# ESP32-H2 register map
Vendor: ESPRESSIF SYSTEMS (SHANGHAI) CO., LTD.; Series: ESP32 H-Series; File version: 12
CPU: RV32IMAC r0p0, little endian, no MPU, no FPU, 0 interrupt priority bits
Address unit: 32 bits
Registers are 32-bit, read-write, reset 0x0 unless marked. A register's access mark holds for its fields unless they carry their own. Offsets are from the block's base; [hi:lo] are bit positions; {n}, {i} and the like mark numbered series.

## LP_PERI — LP_PERI Peripheral
Base 0x600B2800
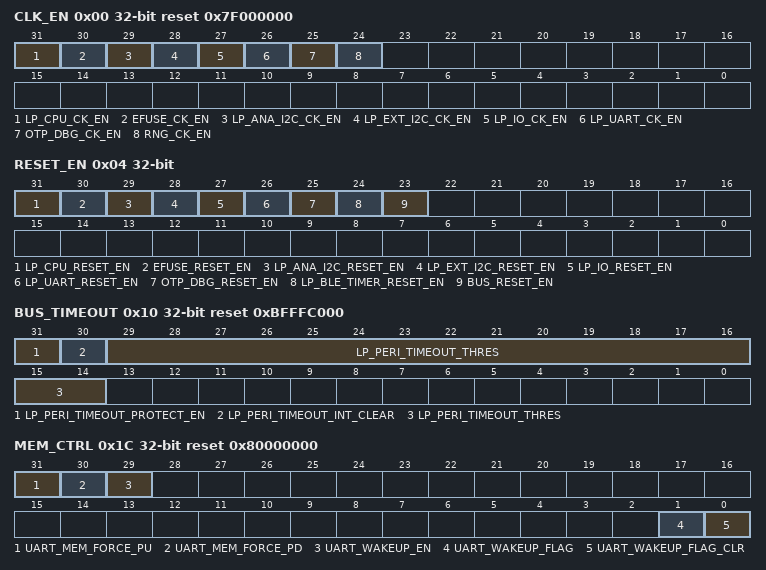
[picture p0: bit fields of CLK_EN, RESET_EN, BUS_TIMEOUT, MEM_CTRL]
0x00 CLK_EN reset 0x7F000000 — need_des
  [31] LP_CPU_CK_EN — need_des
  [30] EFUSE_CK_EN — need_des
  [29] LP_ANA_I2C_CK_EN — need_des
  [28] LP_EXT_I2C_CK_EN — need_des
  [27] LP_IO_CK_EN — need_des
  [26] LP_UART_CK_EN — need_des
  [25] OTP_DBG_CK_EN — need_des
  [24] RNG_CK_EN — need_des
0x04 RESET_EN access per field — need_des
  [31] LP_CPU_RESET_EN wo — need_des
  [30] EFUSE_RESET_EN rw — need_des
  [29] LP_ANA_I2C_RESET_EN rw — need_des
  [28] LP_EXT_I2C_RESET_EN rw — need_des
  [27] LP_IO_RESET_EN rw — need_des
  [26] LP_UART_RESET_EN rw — need_des
  [25] OTP_DBG_RESET_EN rw — need_des
  [24] LP_BLE_TIMER_RESET_EN rw — need_des
  [23] BUS_RESET_EN wo — need_des
0x08 RNG_DATA ro — need_des
  [31:0] RND_DATA
0x0C CPU reset 0x80000000 — need_des
  [31] LPCORE_DBGM_UNAVALIABLE
0x10 BUS_TIMEOUT access per field reset 0xBFFFC000 — need_des
  [31] LP_PERI_TIMEOUT_PROTECT_EN rw — need_des
  [30] LP_PERI_TIMEOUT_INT_CLEAR wo — need_des
  [29:14] LP_PERI_TIMEOUT_THRES rw — need_des
0x14 BUS_TIMEOUT_ADDR ro — need_des
  [31:0] LP_PERI_TIMEOUT_ADDR
0x18 BUS_TIMEOUT_UID ro — need_des
  [6:0] LP_PERI_TIMEOUT_UID
0x1C MEM_CTRL access per field reset 0x80000000 — need_des
  [31] UART_MEM_FORCE_PU rw — need_des
  [30] UART_MEM_FORCE_PD rw — need_des
  [29] UART_WAKEUP_EN rw — need_des
  [1] UART_WAKEUP_FLAG rw — need_des
  [0] UART_WAKEUP_FLAG_CLR wo — need_des
0x20 INTERRUPT_SOURCE ro — need_des
  [5:0] LP_INTERRUPT_SOURCE — BIT5~BIT0: pmu_lp_int, modem_lp_int, lp_timer_lp_int, lp_uart_int, lp_i2c_int, lp_io_int
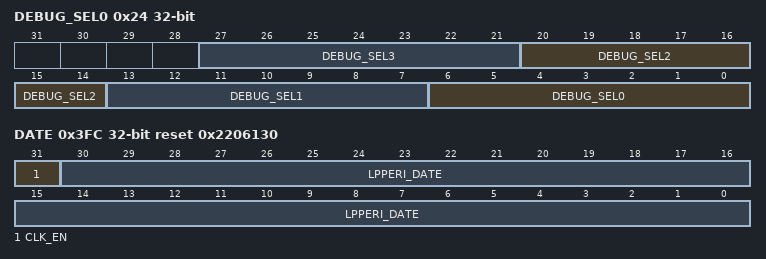
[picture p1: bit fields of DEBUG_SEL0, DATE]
0x24 DEBUG_SEL0 — need des
  [7n+6:7n] DEBUG_SEL{n} (n=0..3) — need des
0x28 DEBUG_SEL1 — need des
  [6:0] DEBUG_SEL4
0x3FC DATE reset 0x2206130 — need_des
  [31] CLK_EN — need_des
  [30:0] LPPERI_DATE — need_des

## LP_ANA — LP_ANA Peripheral
Base 0x600B2C00
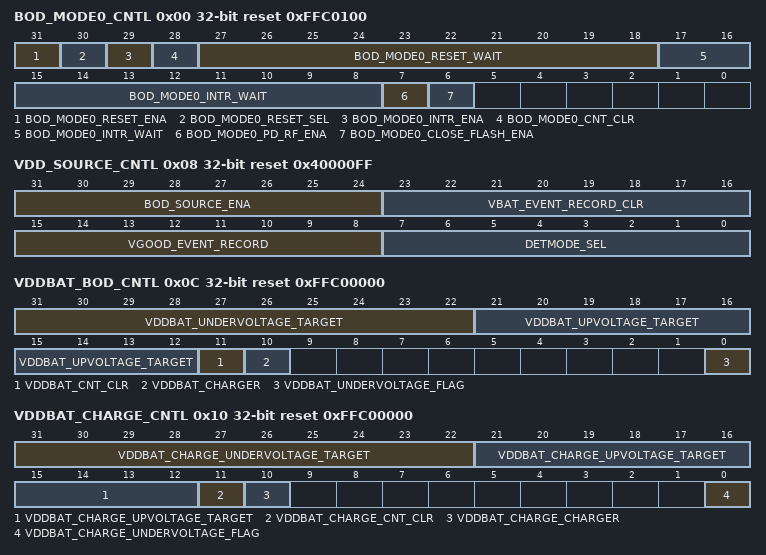
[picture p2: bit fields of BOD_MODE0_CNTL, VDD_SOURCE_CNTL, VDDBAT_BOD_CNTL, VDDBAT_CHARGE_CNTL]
0x00 BOD_MODE0_CNTL reset 0xFFC0100 — need_des
  [31] BOD_MODE0_RESET_ENA — need_des
  [30] BOD_MODE0_RESET_SEL — need_des
  [29] BOD_MODE0_INTR_ENA — need_des
  [28] BOD_MODE0_CNT_CLR — need_des
  [27:18] BOD_MODE0_RESET_WAIT — need_des
  [17:8] BOD_MODE0_INTR_WAIT — need_des
  [7] BOD_MODE0_PD_RF_ENA — need_des
  [6] BOD_MODE0_CLOSE_FLASH_ENA — need_des
0x04 BOD_MODE1_CNTL — need_des
  [31] BOD_MODE1_RESET_ENA
0x08 VDD_SOURCE_CNTL access per field reset 0x40000FF — need_des
  [31:24] BOD_SOURCE_ENA rw — need_des
  [23:16] VBAT_EVENT_RECORD_CLR wo — need_des
  [15:8] VGOOD_EVENT_RECORD ro — need_des
  [7:0] DETMODE_SEL rw — need_des
0x0C VDDBAT_BOD_CNTL access per field reset 0xFFC00000 — need_des
  [31:22] VDDBAT_UNDERVOLTAGE_TARGET rw — need_des
  [21:12] VDDBAT_UPVOLTAGE_TARGET rw — need_des
  [11] VDDBAT_CNT_CLR rw — need_des
  [10] VDDBAT_CHARGER rw — need_des
  [0] VDDBAT_UNDERVOLTAGE_FLAG ro — need_des
0x10 VDDBAT_CHARGE_CNTL access per field reset 0xFFC00000 — need_des
  [31:22] VDDBAT_CHARGE_UNDERVOLTAGE_TARGET rw — need_des
  [21:12] VDDBAT_CHARGE_UPVOLTAGE_TARGET rw — need_des
  [11] VDDBAT_CHARGE_CNT_CLR rw — need_des
  [10] VDDBAT_CHARGE_CHARGER rw — need_des
  [0] VDDBAT_CHARGE_UNDERVOLTAGE_FLAG ro — need_des
0x14 CK_GLITCH_CNTL — need_des
  [31] CK_GLITCH_RESET_ENA
0x18 PG_GLITCH_CNTL — need_des
  [31] POWER_GLITCH_RESET_ENA
0x1C FIB_ENABLE reset 0xFFFFFFFF — need_des
  [31:0] ANA_FIB_ENA
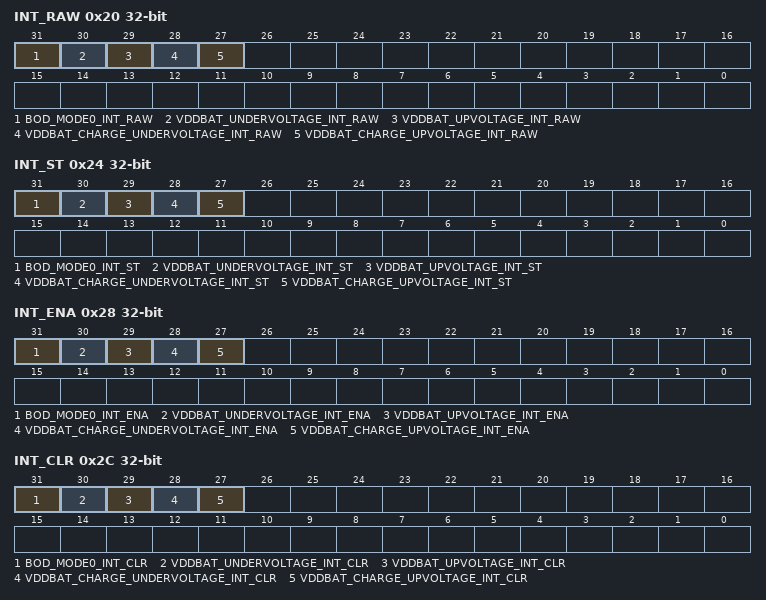
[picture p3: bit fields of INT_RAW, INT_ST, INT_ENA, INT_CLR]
0x20 INT_RAW — need_des
  [31] BOD_MODE0_INT_RAW — need_des
  [30] VDDBAT_UNDERVOLTAGE_INT_RAW — need_des
  [29] VDDBAT_UPVOLTAGE_INT_RAW — need_des
  [28] VDDBAT_CHARGE_UNDERVOLTAGE_INT_RAW — need_des
  [27] VDDBAT_CHARGE_UPVOLTAGE_INT_RAW — need_des
0x24 INT_ST ro — need_des
  [31] BOD_MODE0_INT_ST — need_des
  [30] VDDBAT_UNDERVOLTAGE_INT_ST — need_des
  [29] VDDBAT_UPVOLTAGE_INT_ST — need_des
  [28] VDDBAT_CHARGE_UNDERVOLTAGE_INT_ST — need_des
  [27] VDDBAT_CHARGE_UPVOLTAGE_INT_ST — need_des
0x28 INT_ENA — need_des
  [31] BOD_MODE0_INT_ENA — need_des
  [30] VDDBAT_UNDERVOLTAGE_INT_ENA — need_des
  [29] VDDBAT_UPVOLTAGE_INT_ENA — need_des
  [28] VDDBAT_CHARGE_UNDERVOLTAGE_INT_ENA — need_des
  [27] VDDBAT_CHARGE_UPVOLTAGE_INT_ENA — need_des
0x2C INT_CLR wo — need_des
  [31] BOD_MODE0_INT_CLR — need_des
  [30] VDDBAT_UNDERVOLTAGE_INT_CLR — need_des
  [29] VDDBAT_UPVOLTAGE_INT_CLR — need_des
  [28] VDDBAT_CHARGE_UNDERVOLTAGE_INT_CLR — need_des
  [27] VDDBAT_CHARGE_UPVOLTAGE_INT_CLR — need_des
0x30 LP_INT_RAW — need_des
  [31] BOD_MODE0_LP_INT_RAW
0x34 LP_INT_ST ro — need_des
  [31] BOD_MODE0_LP_INT_ST
0x38 LP_INT_ENA — need_des
  [31] BOD_MODE0_LP_INT_ENA
0x3C LP_INT_CLR wo — need_des
  [31] BOD_MODE0_LP_INT_CLR
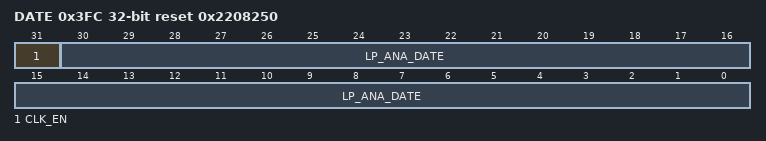
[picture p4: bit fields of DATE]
0x3FC DATE reset 0x2208250 — need_des
  [31] CLK_EN — need_des
  [30:0] LP_ANA_DATE — need_des
